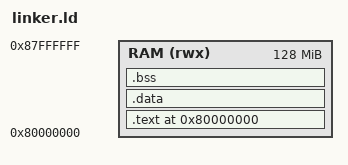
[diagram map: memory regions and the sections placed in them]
ENTRY(_start)

MEMORY
{
    RAM (rwx) : ORIGIN = 0x80000000, LENGTH = 128M
}

SECTIONS
{
    . = ORIGIN(RAM);

    .text : ALIGN(4)
    {
        KEEP(*(.text.entry))
        *(.text*)
        *(.rodata*)
    } > RAM

    .data : ALIGN(4)
    {
        *(.data*)
    } > RAM

    .bss : ALIGN(4)
    {
        __bss_start = .;
        *(.bss*)
        *(COMMON)
        __bss_end = .;
    } > RAM

    _stack_top = ORIGIN(RAM) + LENGTH(RAM);
}
